AUTOSAR XML (schema 00050)
package /DBC_SysDesc_Can_Network_test0/Pkg_Cluster
  can cluster Can_Network_test0: baudrate=500000, protocol-name=CAN
    can physical channel Can_Network_test0_Channel: comm-connectors=Conn_Can_Network_CANNODE_0_New_Node_1
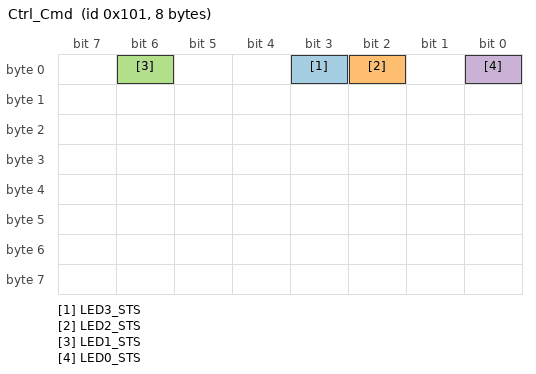
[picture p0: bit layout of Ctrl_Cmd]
      frame Ctrl_Cmd: id 0x101, to New_Node_1, frame-length=8, can-addressing-mode=STANDARD, can-fd-frame-support=true, can-frame-rx-behavior=CAN-FD
        carries pdu Ctrl_Cmd: packing-byte-order=big-endian, start-position=7
        pdu Ctrl_Cmd: length=8, transmission-mode-false-timing=cyclic-timing=time-period=0.1, transmission-mode-true-timing=cyclic-timing=time-period=0.1
          transmission-mode-conditions:
            {data-filter={data-filter-type=ALWAYS, max=0, min=0, offset=0}, i-signal-in-i-pdu=LED3_STS}
            {data-filter={data-filter-type=ALWAYS, max=0, min=0, offset=0}, i-signal-in-i-pdu=LED2_STS}
            {data-filter={data-filter-type=ALWAYS, max=0, min=0, offset=0}, i-signal-in-i-pdu=LED1_STS}
            {data-filter={data-filter-type=ALWAYS, max=0, min=0, offset=0}, i-signal-in-i-pdu=LED0_STS}
          signal LED3_STS: start 3, 1 bit, big-endian, base-type=uint8, compu {raw=phys for phys 0}, to New_Node_1
          signal LED2_STS: start 2, 1 bit, big-endian, base-type=uint8, compu {raw=phys for phys 0}, to New_Node_1
          signal LED1_STS: start 6, 1 bit, big-endian, base-type=uint8, compu {raw=phys for phys 0}, to New_Node_1
          signal LED0_STS: start 0, 1 bit, big-endian, base-type=uint8, compu {raw=phys for phys 0}, to New_Node_1
      frame Uds_Rx_Fun: id 0x7DF, to New_Node_1, frame-length=8, can-addressing-mode=STANDARD, can-fd-frame-support=true, can-frame-rx-behavior=CAN-FD
        carries pdu Uds_Rx_Fun: packing-byte-order=big-endian, start-position=7
        dcm i pdu Uds_Rx_Fun: length=8
      frame Uds_Rx_Phy: id 0x765, to New_Node_1, frame-length=8, can-addressing-mode=STANDARD, can-fd-frame-support=true, can-frame-rx-behavior=CAN-FD
        carries pdu Uds_Rx_Phy: packing-byte-order=big-endian, start-position=7
        dcm i pdu Uds_Rx_Phy: length=8
      frame Can_Nm: id 0x600, from New_Node_1, frame-length=8, can-addressing-mode=STANDARD, can-fd-frame-support=true, can-frame-tx-behavior=CAN-FD
        carries pdu Can_Nm: packing-byte-order=big-endian, start-position=7
        nm pdu Can_Nm: has-dynamic-length=false, length=8, nm-data-information=true, nm-vote-information=true
          signal Can_Nm_msg: start 7, 64 bit, big-endian, base-type=uint64, compu {raw=phys for phys 0}
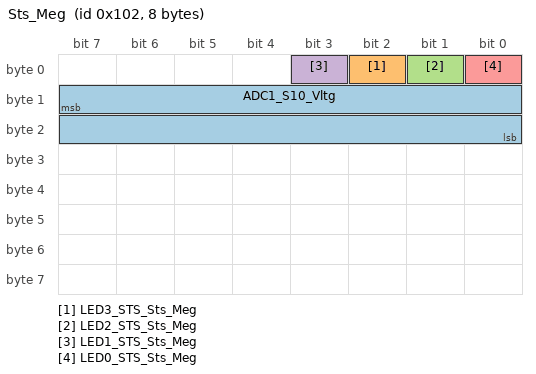
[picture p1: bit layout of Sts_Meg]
      frame Sts_Meg: id 0x102, from New_Node_1, frame-length=8, can-addressing-mode=STANDARD, can-fd-frame-support=true, can-frame-tx-behavior=CAN-FD
        carries pdu Sts_Meg: packing-byte-order=big-endian, start-position=7
        pdu Sts_Meg: length=8, transmission-mode-false-timing=cyclic-timing=time-period=0.1, transmission-mode-true-timing=cyclic-timing=time-period=0.1
          transmission-mode-conditions:
            {data-filter={data-filter-type=NEW-IS-WITHIN, max=0, min=0, offset=0}, i-signal-in-i-pdu=ADC1_S10_Vltg}
            {data-filter={data-filter-type=ALWAYS, max=0, min=0, offset=0}, i-signal-in-i-pdu=LED3_STS_Sts_Meg}
            {data-filter={data-filter-type=ALWAYS, max=0, min=0, offset=0}, i-signal-in-i-pdu=LED2_STS_Sts_Meg}
            {data-filter={data-filter-type=ALWAYS, max=0, min=0, offset=0}, i-signal-in-i-pdu=LED1_STS_Sts_Meg}
            {data-filter={data-filter-type=ALWAYS, max=0, min=0, offset=0}, i-signal-in-i-pdu=LED0_STS_Sts_Meg}
          signal ADC1_S10_Vltg: start 15, 16 bit, big-endian, base-type=uint16, compu {raw=phys*1000 for phys 0}
          signal LED3_STS_Sts_Meg: start 2, 1 bit, big-endian, base-type=uint8, compu {raw=phys for phys 0}
          signal LED2_STS_Sts_Meg: start 1, 1 bit, big-endian, base-type=uint8, compu {raw=phys for phys 0}
          signal LED1_STS_Sts_Meg: start 3, 1 bit, big-endian, base-type=uint8, compu {raw=phys for phys 0}
          signal LED0_STS_Sts_Meg: start 0, 1 bit, big-endian, base-type=uint8, compu {raw=phys for phys 0}
      frame Uds_Tx: id 0x76D, from New_Node_1, frame-length=8, can-addressing-mode=STANDARD, can-fd-frame-support=true, can-frame-tx-behavior=CAN-FD
        carries pdu Uds_Tx: packing-byte-order=big-endian, start-position=7
        dcm i pdu Uds_Tx: length=8
package /DBC_SysDesc_Can_Network_test0/Pkg_Nm
  nm config NmConfig_0
    can nm cluster CanNmCluster_0: communication-cluster=Can_Network_test0, nm-channel-id=1, nm-channel-sleep-master=false, nm-synchronizing-network=false, nm-busload-reduction-active=false, nm-car-wake-up-filter-enabled=false, nm-car-wake-up-rx-enabled=false, nm-channel-active=false
      can nm node CanNmMode_New_Node_1_Can_Network_CANNODE_0: controller=Can_Network_CANNODE_0, nm-if-ecu=NmEcu_New_Node_1, nm-node-id=1, nm-passive-mode-enabled=false, tx-nm-pdu=Can_Nm, nm-range-config={lower-can-id=1536, upper-can-id=1536}
    nm-if-ecus:
      nm ecu NmEcu_New_Node_1:
        bus-specific-nm-ecu=can-nm-ecu=nm-repeat-msg-indication-enabled=false
        ecu-instance=New_Node_1
        nm-bus-synchronization-enabled=false
        nm-com-control-enabled=false
        nm-coordinator=nm-node=CanNmMode_New_Node_1_Can_Network_CANNODE_0
        nm-multiple-channels-enabled=false
        nm-node-detection-enabled=false
        nm-node-id-enabled=false
        nm-passive-mode-enabled=false
        nm-pdu-rx-indication-enabled=false
        nm-remote-sleep-ind-enabled=false
        nm-repeat-msg-ind-enabled=false
        nm-state-change-ind-enabled=false
        nm-user-data-enabled=false
package /DBC_SysDesc_Can_Network_test0/Pkg_Ecu
  ecu instance New_Node_1: com-configuration-gw-time-base=0.005, com-configuration-rx-time-base=0.01, com-configuration-tx-time-base=0.01, sleep-mode-supported=false, wake-up-over-bus-supported=false
    can communication controller Can_Network_CANNODE_0: can-controller-attributes=can-controller-configuration={prop-seg=0, sync-jump-width=0, time-seg-1=10, time-seg-2=0}
    can communication connector Conn_Can_Network_CANNODE_0_New_Node_1: comm-controller=Can_Network_CANNODE_0
